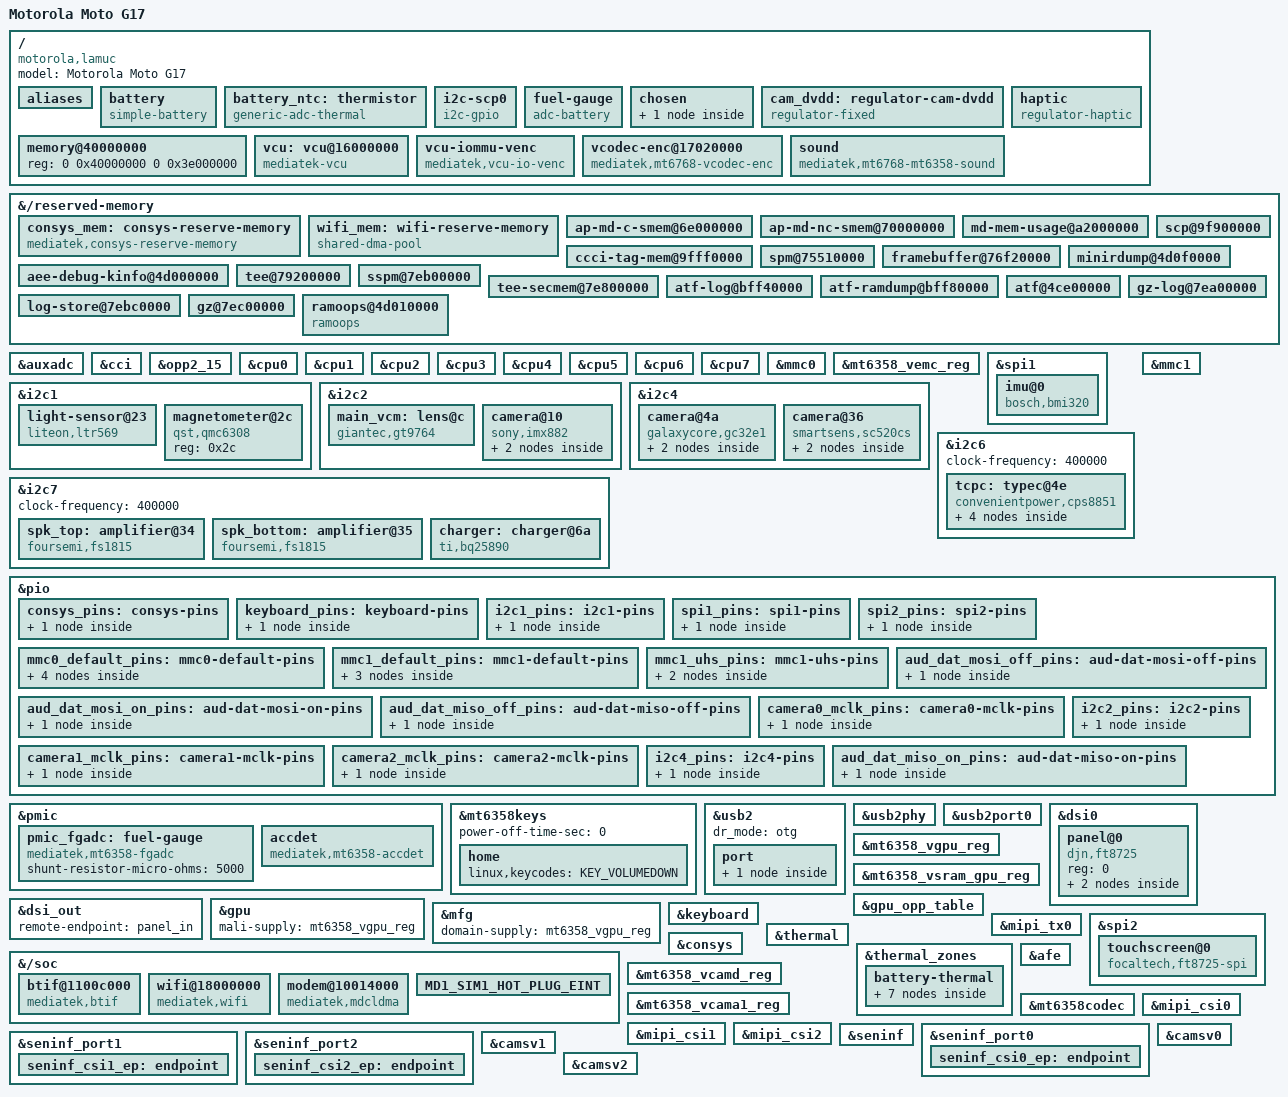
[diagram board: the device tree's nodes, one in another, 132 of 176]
// SPDX-License-Identifier: GPL-2.0-only
/*
 * Motorola Moto G17 (lamuc), booted from U-Boot chainloaded by stock lk.
 * MT6358 regulators, display on lk's panel init.
 */

/dts-v1/;

#include "mt6768.dtsi"
#include "mt6358.dtsi"
#include <dt-bindings/gpio/gpio.h>
#include <dt-bindings/iio/adc/mediatek,mt6358-auxadc.h>
#include <dt-bindings/usb/pd.h>

/ {
	model = "Motorola Moto G17";
	compatible = "motorola,lamuc", "mediatek,mt6768";

	aliases {
		mmc0 = &mmc0;
		mmc1 = &mmc1;
	};

	/* vendor gauge profile battery1_profile_t1 (25 C); battery ID unread */
	battery: battery {
		compatible = "simple-battery";
		device-chemistry = "lithium-ion-polymer";
		charge-full-design-microamp-hours = <5200000>;
		voltage-min-design-microvolt = <3400000>;
		voltage-max-design-microvolt = <4448000>;
		/* measured, 49 mV sag at 623 mA (profile: 88-93 mOhm at 25 C) */
		factory-internal-resistance-micro-ohms = <80000>;
		ocv-capacity-celsius = <25>;
		ocv-capacity-table-0 = <4461000 100>, <4400974 95>, <4349768 90>,
			<4293264 85>, <4232175 80>, <4170600 75>, <4112594 70>,
			<4058013 65>, <4008020 60>, <3946004 55>, <3896000 50>,
			<3864312 45>, <3838800 40>, <3817727 35>, <3799709 30>,
			<3775875 25>, <3752462 20>, <3722573 15>, <3696189 10>,
			<3667100 5>, <3205000 0>;
	};

	/*
	 * 10k NTC (vendor table = NCP15XH103), 24k pull-up to 2.8 V. As
	 * generic-adc-thermal so the fuel gauge can read it over IIO.
	 */
	battery_ntc: thermistor {
		compatible = "generic-adc-thermal";
		io-channels = <&pmic_adc MT6358_AUXADC_BAT_TEMP>;
		io-channel-names = "sensor-channel";
		#io-channel-cells = <0>;
		#thermal-sensor-cells = <0>;
		/* mV = 2800 * R / (R + 24k) at 5 C steps */
		temperature-lookup-table =
			<(-40000) 2494>, <(-35000) 2410>, <(-30000) 2311>,
			<(-25000) 2198>, <(-20000) 2071>, <(-15000) 1935>,
			<(-10000) 1790>, <(-5000) 1639>, <0 1488>,
			<5000 1340>, <10000 1197>, <15000 1062>,
			<20000 938>, <25000 824>, <30000 720>, <35000 629>,
			<40000 548>, <45000 476>, <50000 414>, <55000 359>,
			<60000 312>, <65000 272>, <70000 238>, <75000 208>,
			<80000 182>, <85000 160>, <90000 141>, <95000 124>,
			<100000 109>, <105000 97>, <110000 86>, <115000 76>,
			<120000 68>, <125000 61>;
	};

	/* the SCP's other sensor bus (SCP_SDA0/SCL0); no AP I2C function there */
	i2c-scp0 {
		compatible = "i2c-gpio";
		sda-gpios = <&pio 15 (GPIO_ACTIVE_HIGH | GPIO_OPEN_DRAIN)>;
		scl-gpios = <&pio 16 (GPIO_ACTIVE_HIGH | GPIO_OPEN_DRAIN)>;
		i2c-gpio,delay-us = <2>;
		#address-cells = <1>;
		#size-cells = <0>;
	};

	fuel-gauge {
		compatible = "adc-battery";
		io-channels = <&pmic_adc MT6358_AUXADC_BATADC>, <&pmic_fgadc>,
			      <&battery_ntc>;
		io-channel-names = "voltage", "current", "temperature";
		monitored-battery = <&battery>;
		power-supplies = <&charger>;
	};

	chosen {
		/* lk's second framebuffer page, what the panel scans out */
		framebuffer@77916000 {
			compatible = "simple-framebuffer";
			reg = <0 0x77916000 0 (1080 * 2400 * 4)>;
			width = <1080>;
			height = <2400>;
			stride = <(1080 * 4)>;
			format = "a8r8g8b8";
		};
	};

	/* DVDD of the front (GC32E1) and auxiliary (SC520CS) cameras */
	cam_dvdd: regulator-cam-dvdd {
		compatible = "regulator-fixed";
		regulator-name = "cam_dvdd";
		regulator-min-microvolt = <1200000>;
		regulator-max-microvolt = <1200000>;
		gpio = <&pio 178 GPIO_ACTIVE_HIGH>;
		enable-active-high;
	};

	/* stock vib_vol 9 is VIBR VOSEL 9, 2.8 V */
	haptic {
		compatible = "regulator-haptic";
		haptic-supply = <&mt6358_vibr_reg>;
		min-microvolt = <2800000>;
		max-microvolt = <2800000>;
	};

	/* replaced by U-Boot with lk's figure */
	memory@40000000 {
		device_type = "memory";
		reg = <0 0x40000000 0 0x3e000000>;
	};
};

/*
 * lk's mblock reservations (recon/lk-memory-map.txt). Listing them here,
 * with no-map, makes U-Boot skip its own copies, which carry no no-map.
 */
&{/reserved-memory} {
	/* vendor CONNSYS stack (tools/build-wifi.sh); 16 MiB aligned for the EMI remap */
	consys_mem: consys-reserve-memory {
		compatible = "mediatek,consys-reserve-memory";
		no-map;
		size = <0 0x400000>;
		alignment = <0 0x1000000>;
		alloc-ranges = <0 0x40000000 0 0x80000000>;
	};

	wifi_mem: wifi-reserve-memory {
		compatible = "shared-dma-pool";
		no-map;
		size = <0 0x410000>;
		alignment = <0 0x1000000>;
		alloc-ranges = <0 0x40000000 0 0x80000000>;
	};

	ap-md-c-smem@6e000000 {
		reg = <0x0 0x6e000000 0x0 0x01620000>;
		no-map;
	};
	ap-md-nc-smem@70000000 {
		reg = <0x0 0x70000000 0x0 0x008e0000>;
		no-map;
	};
	md-mem-usage@a2000000 {
		reg = <0x0 0xa2000000 0x0 0x10000000>;
		no-map;
	};
	ccci-tag-mem@9fff0000 {
		reg = <0x0 0x9fff0000 0x0 0x00010000>;
		no-map;
	};
	scp@9f900000 {
		reg = <0x0 0x9f900000 0x0 0x00600000>;
		no-map;
	};
	spm@75510000 {
		reg = <0x0 0x75510000 0x0 0x00010000>;
		no-map;
	};
	framebuffer@76f20000 {
		reg = <0x0 0x76f20000 0x0 0x022e0000>;
		no-map;
	};
	minirdump@4d0f0000 {
		reg = <0x0 0x4d0f0000 0x0 0x00010000>;
		no-map;
	};
	aee-debug-kinfo@4d000000 {
		reg = <0x0 0x4d000000 0x0 0x00010000>;
		no-map;
	};
	tee@79200000 {
		reg = <0x0 0x79200000 0x0 0x05600000>;
		no-map;
	};
	sspm@7eb00000 {
		reg = <0x0 0x7eb00000 0x0 0x000c0000>;
		no-map;
	};
	tee-secmem@7e800000 {
		reg = <0x0 0x7e800000 0x0 0x00200000>;
		no-map;
	};
	atf-log@bff40000 {
		reg = <0x0 0xbff40000 0x0 0x00040000>;
		no-map;
	};
	atf-ramdump@bff80000 {
		reg = <0x0 0xbff80000 0x0 0x00080000>;
		no-map;
	};
	atf@4ce00000 {
		reg = <0x0 0x4ce00000 0x0 0x00060000>;
		no-map;
	};
	log-store@7ebc0000 {
		reg = <0x0 0x7ebc0000 0x0 0x00040000>;
		no-map;
	};
	gz-log@7ea00000 {
		reg = <0x0 0x7ea00000 0x0 0x00041000>;
		no-map;
	};
	gz@7ec00000 {
		reg = <0x0 0x7ec00000 0x0 0x01400000>;
		no-map;
	};

	/* console zone at +0x20000 is where U-Boot's memlog writes too */
	ramoops@4d010000 {
		compatible = "ramoops";
		reg = <0 0x4d010000 0 0xe0000>;
		record-size = <0x10000>;
		console-size = <0x40000>;
		pmsg-size = <0x80000>;
	};
};

&auxadc {
	status = "okay";
};

&cci {
	proc-supply = <&mt6358_vproc12_reg>;
	sram-supply = <&mt6358_vsram_proc12_reg>;
};

/* vendor's top CCI OPP; the dtsi's 1277 MHz @ 1006 mV is not in the k68 tables */
&opp2_15 {
	opp-hz = /bits/ 64 <1187000000>;
	opp-microvolt = <943750>;
};

&cpu0 {
	proc-supply = <&mt6358_vproc12_reg>;
	sram-supply = <&mt6358_vsram_proc12_reg>;
};

&cpu1 {
	proc-supply = <&mt6358_vproc12_reg>;
	sram-supply = <&mt6358_vsram_proc12_reg>;
};

&cpu2 {
	proc-supply = <&mt6358_vproc12_reg>;
	sram-supply = <&mt6358_vsram_proc12_reg>;
};

&cpu3 {
	proc-supply = <&mt6358_vproc12_reg>;
	sram-supply = <&mt6358_vsram_proc12_reg>;
};

&cpu4 {
	proc-supply = <&mt6358_vproc12_reg>;
	sram-supply = <&mt6358_vsram_proc12_reg>;
};

&cpu5 {
	proc-supply = <&mt6358_vproc12_reg>;
	sram-supply = <&mt6358_vsram_proc12_reg>;
};

&cpu6 {
	proc-supply = <&mt6358_vproc11_reg>;
	sram-supply = <&mt6358_vsram_proc11_reg>;
};

&cpu7 {
	proc-supply = <&mt6358_vproc11_reg>;
	sram-supply = <&mt6358_vsram_proc11_reg>;
};

/* eMMC, conservatively: high speed only, no hw reset, no CQE */
&mmc0 {
	pinctrl-names = "default", "state_uhs";
	pinctrl-0 = <&mmc0_default_pins>;
	pinctrl-1 = <&mmc0_default_pins>;
	bus-width = <8>;
	max-frequency = <200000000>;
	cap-mmc-highspeed;
	mmc-hs200-1_8v;
	mmc-hs400-1_8v;
	hs400-ds-delay = <0x12814>;
	non-removable;
	no-sd;
	no-sdio;
	vmmc-supply = <&mt6358_vemc_reg>;
	vqmmc-supply = <&mt6358_vio18_reg>;
	status = "okay";
};

&mt6358_vemc_reg {
	regulator-min-microvolt = <3000000>;
	regulator-max-microvolt = <3000000>;
};

/* microSD, conservatively: high speed only */
&spi1 {
	pinctrl-names = "default";
	pinctrl-0 = <&spi1_pins>;
	/* SPI1_A_* */
	mediatek,pad-select = <0>;
	status = "okay";

	imu@0 {
		compatible = "bosch,bmi320", "bosch,bmi323";
		reg = <0>;
		spi-max-frequency = <10000000>;
		mount-matrix = "0", "-1", "0",
			       "1", "0", "0",
			       "0", "0", "1";
	};
};

/* sensors, behind the SCP on stock */
&i2c1 {
	clock-frequency = <400000>;
	pinctrl-names = "default";
	pinctrl-0 = <&i2c1_pins>;
	status = "okay";

	light-sensor@23 {
		compatible = "liteon,ltr569";
		reg = <0x23>;
		/* ~280 counts open, thousands when covered */
		proximity-near-level = <1500>;
	};

	magnetometer@2c {
		compatible = "qst,qmc6308";
		reg = <0x2c>;
	};
};

/* pins muxed by the bootloader, as in the vendor DT */
/* main rear camera */
&i2c2 {
	clock-frequency = <400000>;
	pinctrl-names = "default";
	pinctrl-0 = <&i2c2_pins>;
	status = "okay";

	main_vcm: lens@c {
		compatible = "giantec,gt9764";
		reg = <0x0c>;
		vdd-supply = <&mt6358_vldo28_reg>;
	};

	camera@10 {
		compatible = "sony,imx882";
		reg = <0x10>;
		pinctrl-names = "default";
		pinctrl-0 = <&camera0_mclk_pins>;
		clocks = <&topckgen CLK_TOP_CAMTG_SEL>;
		assigned-clocks = <&topckgen CLK_TOP_CAMTG_SEL>;
		assigned-clock-parents = <&topckgen CLK_TOP_USB20_192M_D8>;
		reset-gpios = <&pio 101 GPIO_ACTIVE_LOW>;
		dovdd-supply = <&mt6358_vcamio_reg>;
		dvdd-supply = <&mt6358_vcamd_reg>;
		avdd-supply = <&mt6358_vcama1_reg>;
		lens-focus = <&main_vcm>;
		orientation = <1>;
		rotation = <90>;

		port {
			imx882_ep: endpoint {
				remote-endpoint = <&seninf_csi0_ep>;
				data-lanes = <1 2 3 4>;
				link-frequencies = /bits/ 64 <500000000 878000000>;
			};
		};
	};
};

/* front and auxiliary rear cameras */
&i2c4 {
	clock-frequency = <400000>;
	pinctrl-names = "default";
	pinctrl-0 = <&i2c4_pins>;
	status = "okay";

	camera@4a {
		compatible = "galaxycore,gc32e1";
		reg = <0x4a>;
		pinctrl-names = "default";
		pinctrl-0 = <&camera1_mclk_pins>;
		clocks = <&topckgen CLK_TOP_CAMTG1_SEL>;
		assigned-clocks = <&topckgen CLK_TOP_CAMTG1_SEL>;
		assigned-clock-parents = <&topckgen CLK_TOP_USB20_192M_D8>;
		reset-gpios = <&pio 109 GPIO_ACTIVE_LOW>;
		dovdd-supply = <&mt6358_vcamio_reg>;
		dvdd-supply = <&cam_dvdd>;
		avdd-supply = <&mt6358_vcama2_reg>;
		orientation = <0>;
		rotation = <90>;

		port {
			gc32e1_ep: endpoint {
				remote-endpoint = <&seninf_csi2_ep>;
				data-lanes = <1 2 3 4>;
				link-frequencies = /bits/ 64 <403200000>;
			};
		};
	};

	camera@36 {
		compatible = "smartsens,sc520cs";
		reg = <0x36>;
		pinctrl-names = "default";
		pinctrl-0 = <&camera2_mclk_pins>;
		clocks = <&topckgen CLK_TOP_CAMTG2_SEL>;
		assigned-clocks = <&topckgen CLK_TOP_CAMTG2_SEL>;
		assigned-clock-parents = <&topckgen CLK_TOP_USB20_192M_D8>;
		reset-gpios = <&pio 102 GPIO_ACTIVE_LOW>;
		dovdd-supply = <&mt6358_vcamio_reg>;
		dvdd-supply = <&cam_dvdd>;
		avdd-supply = <&mt6358_vcama2_reg>;
		orientation = <1>;
		rotation = <270>;

		port {
			sc520cs_ep: endpoint {
				remote-endpoint = <&seninf_csi1_ep>;
				data-lanes = <1 2>;
				link-frequencies = /bits/ 64 <450000000>;
			};
		};
	};
};

&i2c6 {
	clock-frequency = <400000>;
	status = "okay";

	/*
	 * CPS8851, an RT1711H-style TCPC (VID 0x315c). The vendor DT puts it
	 * at 0x4a and an sc2150 at 0x4e; on this unit only 0x4e answers, with
	 * the CPS8851 IDs.
	 */
	tcpc: typec@4e {
		compatible = "convenientpower,cps8851";
		reg = <0x4e>;
		interrupts-extended = <&pio 4 IRQ_TYPE_LEVEL_LOW>;

		connector {
			compatible = "usb-c-connector";
			label = "USB-C";
			/* sink only until VBUS out (charger boost) is wired up */
			power-role = "sink";
			/* PD hard reset resets the CPS8851's registers; TCPM then loses the port */
			pd-disable;
			typec-power-opmode = "default";
			self-powered;
			data-role = "device";
			sink-pdos = <PDO_FIXED(5000, 2000, PDO_FIXED_USB_COMM)>;
			op-sink-microwatt = <10000000>;

			ports {
				#address-cells = <1>;
				#size-cells = <0>;

				port@0 {
					reg = <0>;

					tcpc_hs: endpoint {
						remote-endpoint = <&usb_role_sw>;
					};
				};
			};
		};
	};
};

&i2c7 {
	clock-frequency = <400000>;
	status = "okay";

	/* analog in from the MT6358 receiver output; earpiece, doubles as top speaker */
	spk_top: amplifier@34 {
		compatible = "foursemi,fs1815";
		reg = <0x34>;
		sound-name-prefix = "Top";
	};

	/* analog in from the MT6358 LINEOUT L */
	spk_bottom: amplifier@35 {
		compatible = "foursemi,fs1815";
		reg = <0x35>;
		sound-name-prefix = "Bottom";
	};

	/* Suncore CX25890H, a register-compatible BQ25890 clone (same PN) */
	charger: charger@6a {
		compatible = "ti,bq25890";
		reg = <0x6a>;
		interrupts-extended = <&pio 3 IRQ_TYPE_EDGE_FALLING>;
		/* Type-C current advertisement for IINLIM */
		power-supplies = <&tcpc>;
		/* lk leaves it charging; /CE is GPIO150, held low by lk */
		linux,skip-reset;
		/* TS is not the battery NTC: JEITA is battery-thermal's job */
		ti,charge-current = <2048000>;
		ti,battery-regulation-voltage = <4448000>;
		ti,termination-current = <256000>;
		ti,precharge-current = <128000>;
		ti,minimum-sys-voltage = <3500000>;
		ti,boost-voltage = <5126000>;
		ti,boost-max-current = <1650000>;
		#cooling-cells = <2>;
	};
};

&mmc1 {
	pinctrl-names = "default", "state_uhs";
	pinctrl-0 = <&mmc1_default_pins>;
	pinctrl-1 = <&mmc1_uhs_pins>;
	bus-width = <4>;
	max-frequency = <200000000>;
	cap-sd-highspeed;
	sd-uhs-sdr12;
	sd-uhs-sdr25;
	sd-uhs-sdr50;
	sd-uhs-sdr104;
	sd-uhs-ddr50;
	no-mmc;
	no-sdio;
	cd-gpios = <&pio 18 GPIO_ACTIVE_HIGH>;
	vmmc-supply = <&mt6358_vmch_reg>;
	vqmmc-supply = <&mt6358_vmc_reg>;
	status = "okay";
};

&pio {
	consys_pins: consys-pins {
		pins-adie {
			pinmux = <PINMUX_GPIO113__FUNC_CONN_TOP_CLK>,
				 <PINMUX_GPIO114__FUNC_CONN_TOP_DATA>,
				 <PINMUX_GPIO115__FUNC_CONN_BT_CLK>,
				 <PINMUX_GPIO116__FUNC_CONN_BT_DATA>,
				 <PINMUX_GPIO117__FUNC_CONN_WF_CTRL0>,
				 <PINMUX_GPIO118__FUNC_CONN_WF_CTRL1>,
				 <PINMUX_GPIO119__FUNC_CONN_WF_CTRL2>,
				 <PINMUX_GPIO120__FUNC_CONN_WB_PTA>,
				 <PINMUX_GPIO121__FUNC_CONN_HRST_B>;
		};
	};

	keyboard_pins: keyboard-pins {
		pins-col {
			pinmux = <PINMUX_GPIO93__FUNC_KPCOL0>;
			bias-pull-up = <MTK_PUPD_SET_R1R0_10>;
			input-enable;
			input-schmitt-enable;
		};
	};

	/* stock muxes these to the SCP (SCP_SCL1/SDA1) for its sensor hub */
	i2c1_pins: i2c1-pins {
		pins-bus {
			pinmux = <PINMUX_GPIO81__FUNC_SDA1>,
				 <PINMUX_GPIO84__FUNC_SCL1>;
		};
	};

	/* SCP_SPI1 on stock, where the sensor hub firmware drives the IMU */
	spi1_pins: spi1-pins {
		pins-spi {
			pinmux = <PINMUX_GPIO85__FUNC_SPI1_A_MI>,
				 <PINMUX_GPIO86__FUNC_SPI1_A_CSB>,
				 <PINMUX_GPIO87__FUNC_SPI1_A_MO>,
				 <PINMUX_GPIO88__FUNC_SPI1_A_CLK>;
		};
	};

	spi2_pins: spi2-pins {
		pins-spi {
			pinmux = <PINMUX_GPIO25__FUNC_SPI2_CSB>,
				 <PINMUX_GPIO26__FUNC_SPI2_MO>,
				 <PINMUX_GPIO27__FUNC_SPI2_CLK>,
				 <PINMUX_GPIO28__FUNC_SPI2_MI>;
		};
	};

	/* SoC-fixed MSDC0 pins, as on penangf */
	mmc0_default_pins: mmc0-default-pins {
		pins-clk {
			pinmux = <PINMUX_GPIO124__FUNC_MSDC0_CLK>;
			drive-strength = <MTK_DRIVE_4mA>;
			bias-pull-down = <MTK_PUPD_SET_R1R0_10>;
		};

		pins-cmd-dat {
			pinmux = <PINMUX_GPIO123__FUNC_MSDC0_DAT0>,
				 <PINMUX_GPIO128__FUNC_MSDC0_DAT1>,
				 <PINMUX_GPIO125__FUNC_MSDC0_DAT2>,
				 <PINMUX_GPIO132__FUNC_MSDC0_DAT3>,
				 <PINMUX_GPIO126__FUNC_MSDC0_DAT4>,
				 <PINMUX_GPIO129__FUNC_MSDC0_DAT5>,
				 <PINMUX_GPIO127__FUNC_MSDC0_DAT6>,
				 <PINMUX_GPIO130__FUNC_MSDC0_DAT7>,
				 <PINMUX_GPIO122__FUNC_MSDC0_CMD>;
			input-enable;
			drive-strength = <MTK_DRIVE_4mA>;
			bias-pull-up = <MTK_PUPD_SET_R1R0_01>;
		};

		pins-ds {
			pinmux = <PINMUX_GPIO131__FUNC_MSDC0_DSL>;
			drive-strength = <MTK_DRIVE_4mA>;
		};

		pins-rst {
			pinmux = <PINMUX_GPIO133__FUNC_MSDC0_RSTB>;
			drive-strength = <MTK_DRIVE_6mA>;
			bias-pull-up = <MTK_PUPD_SET_R1R0_01>;
		};
	};

	/* raw drive values (mt6768 uses drive_set_raw): 3 = 8 mA, as stock */
	mmc1_default_pins: mmc1-default-pins {
		pins-cmd-dat {
			pinmux = <PINMUX_GPIO164__FUNC_MSDC1_DAT0>,
				 <PINMUX_GPIO163__FUNC_MSDC1_DAT1>,
				 <PINMUX_GPIO162__FUNC_MSDC1_DAT2>,
				 <PINMUX_GPIO161__FUNC_MSDC1_DAT3>,
				 <PINMUX_GPIO170__FUNC_MSDC1_CMD>;
			input-enable;
			input-schmitt-enable;
			drive-strength = <3>;
			bias-pull-up = <MTK_PUPD_SET_R1R0_01>;
		};

		pins-clk {
			pinmux = <PINMUX_GPIO171__FUNC_MSDC1_CLK>;
			input-schmitt-enable;
			drive-strength = <3>;
			bias-pull-down = <MTK_PUPD_SET_R1R0_10>;
		};

		pins-insert {
			pinmux = <PINMUX_GPIO18__FUNC_GPIO18>;
			bias-pull-up;
		};
	};

	/* stock's UHS state: as default, CLK without the pull */
	mmc1_uhs_pins: mmc1-uhs-pins {
		pins-cmd-dat {
			pinmux = <PINMUX_GPIO164__FUNC_MSDC1_DAT0>,
				 <PINMUX_GPIO163__FUNC_MSDC1_DAT1>,
				 <PINMUX_GPIO162__FUNC_MSDC1_DAT2>,
				 <PINMUX_GPIO161__FUNC_MSDC1_DAT3>,
				 <PINMUX_GPIO170__FUNC_MSDC1_CMD>;
			input-enable;
			input-schmitt-enable;
			drive-strength = <3>;
			bias-pull-up = <MTK_PUPD_SET_R1R0_01>;
		};

		pins-clk {
			pinmux = <PINMUX_GPIO171__FUNC_MSDC1_CLK>;
			input-schmitt-enable;
			drive-strength = <3>;
		};
	};

};

&pmic {
	interrupts-extended = <&pio 144 IRQ_TYPE_LEVEL_HIGH>;

	pmic_fgadc: fuel-gauge {
		compatible = "mediatek,mt6358-fgadc";
		#io-channel-cells = <0>;
		/* stock R_FG_VALUE */
		shunt-resistor-micro-ohms = <5000>;
	};

	/* stock settings: MICBIAS1 2.6 V, ACC mic, EINT0 active low */
	accdet: accdet {
		compatible = "mediatek,mt6358-accdet";
		io-channels = <&pmic_adc MT6358_AUXADC_ACCDET>;
		io-channel-names = "accdet";
		mediatek,mic-vol = <6>;
		mediatek,eint-level-pol = <IRQ_TYPE_LEVEL_LOW>;
		mediatek,pwm-deb-setting = <0x500 0x500 0x1 0x1f0 0x800 0x800
					    0x20 0x44 0x0 0x0 0xe 0x0 0x0 0x0 0x0>;
		mediatek,three-key-thr = <0 80 220 400>;
	};
};

/* the PMIC "home" key is Volume Down on this phone */
&mt6358keys {
	/* raw RST_TD code, not seconds: 0 as on stock */
	power-off-time-sec = <0>;

	home {
		linux,keycodes = <KEY_VOLUMEDOWN>;
	};
};

&usb2 {
	dr_mode = "otg";
	status = "okay";

	port {
		usb_role_sw: endpoint {
			remote-endpoint = <&tcpc_hs>;
		};
	};
};

&usb2phy {
	status = "okay";
};

/* stock u2port0 tuning; INTR_CAL stays the efuse autoload */
&usb2port0 {
	mediatek,discth = <7>;
	mediatek,eye-vrt = <7>;
	mediatek,eye-term = <3>;
	mediatek,pre-emphasis = <3>;
};

&dsi0 {
	#address-cells = <1>;
	#size-cells = <0>;
	status = "okay";

	/* lk powers it up and sends the init sequence; see recon/dtbo/dtbo0.dts */
	panel@0 {
		compatible = "djn,ft8725";
		reg = <0>;

		port {
			panel_in: endpoint {
				remote-endpoint = <&dsi_out>;
			};
		};
	};
};

&dsi_out {
	remote-endpoint = <&panel_in>;
};

&gpu {
	mali-supply = <&mt6358_vgpu_reg>;
	status = "okay";
};

&mfg {
	domain-supply = <&mt6358_vgpu_reg>;
};

&mt6358_vgpu_reg {
	regulator-max-microvolt = <800000>;
	regulator-coupled-with = <&mt6358_vsram_gpu_reg>;
	regulator-coupled-max-spread = <100000>;
};

/* vendor: vsram = vgpu + 100 mV */
&mt6358_vsram_gpu_reg {
	/* only coupled to vgpu, nothing else enables it */
	regulator-always-on;
	regulator-min-microvolt = <850000>;
	regulator-max-microvolt = <1050000>;
	regulator-coupled-with = <&mt6358_vgpu_reg>;
	regulator-coupled-max-spread = <100000>;
};

/* the vendor caps MT6768/MT6769 parts at 823 MHz (OPP 7); G85-class go to 1 GHz */
&gpu_opp_table {
	/delete-node/ opp-850000000;
	/delete-node/ opp-875000000;
	/delete-node/ opp-900000000;
	/delete-node/ opp-925000000;
	/delete-node/ opp-950000000;
	/delete-node/ opp-975000000;
	/delete-node/ opp-1000000000;
};

&keyboard {
	pinctrl-names = "default";
	pinctrl-0 = <&keyboard_pins>;
	linux,keymap = <MATRIX_KEY(0x00, 0x00, KEY_VOLUMEUP)>;
	keypad,num-rows = <1>;
	keypad,num-columns = <1>;
	debounce-delay-ms = <32>;
	status = "okay";
};

&mipi_tx0 {
	status = "okay";
};

&spi2 {
	pinctrl-names = "default";
	pinctrl-0 = <&spi2_pins>;
	mediatek,pad-select = <0>;
	status = "okay";

	/* touch side of the FT8725 TDDI, firmware already running */
	touchscreen@0 {
		compatible = "focaltech,ft8725-spi";
		reg = <0>;
		spi-max-frequency = <9600000>;
		/* the vendor driver says mode 0, but only mode 3 gets answers */
		spi-cpol;
		spi-cpha;
		interrupts-extended = <&pio 0 IRQ_TYPE_EDGE_FALLING>;
		reset-gpios = <&pio 36 GPIO_ACTIVE_LOW>;
		/* reports display pixels, same orientation (checked with evtest) */
		touchscreen-size-x = <1080>;
		touchscreen-size-y = <2400>;
	};
};

&thermal {
	status = "okay";
};

&thermal_zones {
	/* vendor JEITA: 4.2 V and less current above 45 C, none above 60 C */
	battery-thermal {
		polling-delay-passive = <5000>;
		polling-delay = <10000>;
		thermal-sensors = <&battery_ntc>;

		trips {
			battery_warm: trip-warm {
				temperature = <45000>;
				hysteresis = <3000>;
				type = "passive";
			};

			battery_hot: trip-hot {
				temperature = <60000>;
				hysteresis = <3000>;
				type = "passive";
			};

			trip-crit {
				temperature = <68000>;
				hysteresis = <0>;
				type = "critical";
			};
		};

		cooling-maps {
			map-warm {
				trip = <&battery_warm>;
				cooling-device = <&charger 1 2>;
			};

			map-hot {
				trip = <&battery_hot>;
				cooling-device = <&charger 3 3>;
			};
		};
	};
};

/*
 * Vendor wmt_drv/btif/gen4m bindings, as in the stock DT: they index reg and
 * interrupts by position. mtk-consys (same compatible) is off for this.
 * Stock's GIC flags are inverted here: its HIGH is LOW behind sysirq.
 */
&consys {
	reg = <0 0x18002000 0 0x1000>, <0 0x10007000 0 0x100>,
	      <0 0x10001000 0 0x1000>, <0 0x10006000 0 0x1000>,
	      <0 0x18007000 0 0x1000>, <0 0x180b1000 0 0x1000>,
	      <0 0x180a3000 0 0x1000>, <0 0x180a5000 0 0x800>,
	      <0 0x180c1000 0 0x1000>, <0 0x18004000 0 0x1000>;
	interrupts = <GIC_SPI 284 IRQ_TYPE_LEVEL_LOW>,
		     <GIC_SPI 78 IRQ_TYPE_LEVEL_LOW>,
		     <GIC_SPI 287 IRQ_TYPE_EDGE_FALLING>;
	memory-region = <&consys_mem>;
	pinctrl-names = "default";
	pinctrl-0 = <&consys_pins>;
	vcn18-supply = <&mt6358_vcn18_reg>;
	vcn28-supply = <&mt6358_vcn28_reg>;
	vcn33_bt-supply = <&mt6358_vcn33_reg>;
	vcn33_wifi-supply = <&mt6358_vcn33_reg>;
	status = "okay";
};

&{/soc} {
	btif@1100c000 {
		compatible = "mediatek,btif";
		reg = <0 0x1100c000 0 0x1000>, <0 0x11000b80 0 0x80>,
		      <0 0x11000c00 0 0x80>;
		interrupts = <GIC_SPI 133 IRQ_TYPE_LEVEL_LOW>,
			     <GIC_SPI 115 IRQ_TYPE_LEVEL_LOW>,
			     <GIC_SPI 141 IRQ_TYPE_LEVEL_LOW>;
		clocks = <&infracfg_ao CLK_INFRA_BTIF>,
			 <&infracfg_ao CLK_INFRA_AP_DMA>;
		clock-names = "btifc", "apdmac";
	};

	wifi@18000000 {
		compatible = "mediatek,wifi";
		reg = <0 0x18000000 0 0x100000>;
		interrupts = <GIC_SPI 285 IRQ_TYPE_LEVEL_LOW>;
		memory-region = <&wifi_mem>;
	};

	/* vendor eccci (modem/ in the g17 repo); MD1 power is done there */
	modem@10014000 {
		compatible = "mediatek,mdcldma";
		reg = <0 0x10014000 0 0x1000>, <0 0x1021b000 0 0x1000>,
		      <0 0x10209000 0 0x1000>, <0 0x1020a000 0 0x1000>;
		interrupts = <GIC_SPI 180 IRQ_TYPE_LEVEL_HIGH>,
			     <GIC_SPI 164 IRQ_TYPE_LEVEL_LOW>,
			     <GIC_SPI 165 IRQ_TYPE_LEVEL_LOW>,
			     <GIC_SPI 75 IRQ_TYPE_EDGE_FALLING>;
		clocks = <&infracfg_ao CLK_INFRA_CLDMA_BCLK>,
			 <&infracfg_ao CLK_INFRA_CCIF_AP>,
			 <&infracfg_ao CLK_INFRA_CCIF_MD>,
			 <&infracfg_ao CLK_INFRA_CCIF1_AP>,
			 <&infracfg_ao CLK_INFRA_CCIF1_MD>,
			 <&infracfg_ao CLK_INFRA_CCIF2_AP>,
			 <&infracfg_ao CLK_INFRA_CCIF2_MD>;
		clock-names = "infra-cldma-bclk", "infra-ccif-ap",
			      "infra-ccif-md", "infra-ccif1-ap",
			      "infra-ccif1-md", "infra-ccif2-ap",
			      "infra-ccif2-md";
		md-vmodem-supply = <&mt6358_vmodem_reg>;
		md-vmodem-microvolt = <750000>;
		mediatek,md_id = <0>;
		mediatek,cldma_capability = <6>;
		mediatek,mdhif_type = <3>;
	};

	/* SIM1 detect for the modem, stock dtbo values; eccci finds it by name */
	MD1_SIM1_HOT_PLUG_EINT {
		interrupts = <0 8>;
		debounce = <0 10000>;
		dedicated = <0 0>;
		src_pin = <0 1>;
		sockettype = <0 0>;
	};
};

&afe {
	pinctrl-names = "aud_dat_mosi_off", "aud_dat_mosi_on",
			"aud_dat_miso_off", "aud_dat_miso_on";
	pinctrl-0 = <&aud_dat_mosi_off_pins>;
	pinctrl-1 = <&aud_dat_mosi_on_pins>;
	pinctrl-2 = <&aud_dat_miso_off_pins>;
	pinctrl-3 = <&aud_dat_miso_on_pins>;
};

/ {

	/*
	 * H.264 encoder through the vendor VCU stack (nix/venc.nix): vpud
	 * programs VENC from userspace, mtk-vcu forwards its GCE command lists.
	 * The reg list is vpud's register map, in stock's order.
	 */
	vcu: vcu@16000000 {
		compatible = "mediatek-vcu";
		reg = <0 0x16000000 0 0x40000>,
		      <0 0x17020000 0 0x10000>,
		      <0 0x19002000 0 0x1000>;
		iommus = <&iommu M4U_PORT_VENC_RCPU>, <&iommu M4U_PORT_VENC_REC>,
			 <&iommu M4U_PORT_VENC_BSDMA>, <&iommu M4U_PORT_VENC_SV_COMV>,
			 <&iommu M4U_PORT_VENC_RD_COMV>, <&iommu M4U_PORT_VENC_CUR_LUMA>,
			 <&iommu M4U_PORT_VENC_CUR_CHROMA>, <&iommu M4U_PORT_VENC_REF_LUMA>,
			 <&iommu M4U_PORT_VENC_REF_CHROMA>;
		mboxes = <&gce 12 CMDQ_THR_PRIO_1>, <&gce 13 CMDQ_THR_PRIO_1>;
		gce-event-names = "venc_eof", "venc_cmdq_pause_done",
				  "venc_mb_done", "venc_128B_cnt_done";
		mediatek,gce-events = <CMDQ_EVENT_VENC_FRAME_DONE>,
				      <CMDQ_EVENT_VENC_PAUSE_DONE>,
				      <CMDQ_EVENT_VENC_MB_DONE>,
				      <CMDQ_EVENT_VENC_128BYTE_CNT_DONE>;
		gce-norm-token = /bits/ 16 <0x2b8>;
		gce-sec-token = /bits/ 16 <0x2b9>;
		mediatek,vcuid = <0>;
		mediatek,vcuname = "vcu";
		mediatek,vcu-off = <0>;
		mediatek,dec-gce-th-num = <0>;
		mediatek,enc-gce-th-num = <2>;
	};

	vcu-iommu-venc {
		compatible = "mediatek,vcu-io-venc";
		iommus = <&iommu M4U_PORT_VENC_RCPU>, <&iommu M4U_PORT_VENC_REC>,
			 <&iommu M4U_PORT_VENC_BSDMA>, <&iommu M4U_PORT_VENC_SV_COMV>,
			 <&iommu M4U_PORT_VENC_RD_COMV>, <&iommu M4U_PORT_VENC_CUR_LUMA>,
			 <&iommu M4U_PORT_VENC_CUR_CHROMA>, <&iommu M4U_PORT_VENC_REF_LUMA>,
			 <&iommu M4U_PORT_VENC_REF_CHROMA>;
		mediatek,vcuid = <0>;
	};

	vcodec-enc@17020000 {
		compatible = "mediatek,mt6768-vcodec-enc";
		reg = <0 0x17020000 0 0x2000>;
		reg-names = "VENC_SYS";
		interrupts = <GIC_SPI 243 IRQ_TYPE_LEVEL_LOW>;
		iommus = <&iommu M4U_PORT_VENC_RCPU>, <&iommu M4U_PORT_VENC_REC>,
			 <&iommu M4U_PORT_VENC_BSDMA>, <&iommu M4U_PORT_VENC_SV_COMV>,
			 <&iommu M4U_PORT_VENC_RD_COMV>, <&iommu M4U_PORT_VENC_CUR_LUMA>,
			 <&iommu M4U_PORT_VENC_CUR_CHROMA>, <&iommu M4U_PORT_VENC_REF_LUMA>,
			 <&iommu M4U_PORT_VENC_REF_CHROMA>;
		clocks = <&vencsys CLK_VENC_SET1_VENC>;
		clock-names = "MT_CG_VENC";
		mediatek,larbs = <&larb4>;
		mediatek,vcu = <&vcu>;
		mediatek,platform = "platform:mt6768";
		mediatek,ipm = <1>;
		venc-disable-hw-break = <1>;
	};
	sound: sound {
		compatible = "mediatek,mt6768-mt6358-sound";
		mediatek,platform = <&afe>;
		mediatek,accdet = <&accdet>;
		audio-aux-devs = <&spk_top>, <&spk_bottom>;
		audio-routing = "Top IN", "Receiver",
				"Bottom IN", "LINEOUT L";
	};
};

&pio {
	/* mtkaif pads to the MT6358 codec, as in the stock DT */
	aud_dat_mosi_off_pins: aud-dat-mosi-off-pins {
		pins-cmd-dat {
			pinmux = <PINMUX_GPIO136__FUNC_GPIO136>,
				 <PINMUX_GPIO137__FUNC_GPIO137>,
				 <PINMUX_GPIO138__FUNC_GPIO138>,
				 <PINMUX_GPIO139__FUNC_GPIO139>;
			input-enable;
			slew-rate = <0>;
			bias-disable;
		};
	};

	aud_dat_mosi_on_pins: aud-dat-mosi-on-pins {
		pins-cmd-dat {
			pinmux = <PINMUX_GPIO136__FUNC_AUD_CLK_MOSI>,
				 <PINMUX_GPIO137__FUNC_AUD_SYNC_MOSI>,
				 <PINMUX_GPIO138__FUNC_AUD_DAT_MOSI0>,
				 <PINMUX_GPIO139__FUNC_AUD_DAT_MOSI1>;
			input-schmitt-enable;
		};
	};

	aud_dat_miso_off_pins: aud-dat-miso-off-pins {
		pins-cmd-dat {
			pinmux = <PINMUX_GPIO140__FUNC_GPIO140>,
				 <PINMUX_GPIO141__FUNC_GPIO141>,
				 <PINMUX_GPIO142__FUNC_GPIO142>,
				 <PINMUX_GPIO143__FUNC_GPIO143>;
			input-enable;
			slew-rate = <0>;
			bias-disable;
		};
	};

	camera0_mclk_pins: camera0-mclk-pins {
		pins {
			pinmux = <PINMUX_GPIO99__FUNC_CMMCLK0>;
			drive-strength = <4>;
		};
	};

	camera1_mclk_pins: camera1-mclk-pins {
		pins {
			pinmux = <PINMUX_GPIO100__FUNC_CMMCLK1>;
			drive-strength = <4>;
		};
	};

	camera2_mclk_pins: camera2-mclk-pins {
		pins {
			pinmux = <PINMUX_GPIO108__FUNC_CMMCLK2>;
			drive-strength = <6>;
		};
	};

	/* nothing else pulls the camera buses up */
	i2c2_pins: i2c2-pins {
		pins {
			pinmux = <PINMUX_GPIO103__FUNC_SCL2>,
				 <PINMUX_GPIO104__FUNC_SDA2>;
			bias-pull-up;
		};
	};

	i2c4_pins: i2c4-pins {
		pins {
			pinmux = <PINMUX_GPIO105__FUNC_SCL4>,
				 <PINMUX_GPIO106__FUNC_SDA4>;
			bias-pull-up;
		};
	};

	aud_dat_miso_on_pins: aud-dat-miso-on-pins {
		pins-cmd-dat {
			pinmux = <PINMUX_GPIO140__FUNC_AUD_CLK_MISO>,
				 <PINMUX_GPIO141__FUNC_AUD_SYNC_MISO>,
				 <PINMUX_GPIO142__FUNC_AUD_DAT_MISO0>,
				 <PINMUX_GPIO143__FUNC_AUD_DAT_MISO1>;
			input-schmitt-enable;
		};
	};
};

/* the PMIC codec, on the internal mtkaif link */
/* IMX882 core and analog */
&mt6358_vcamd_reg {
	regulator-min-microvolt = <1100000>;
	regulator-max-microvolt = <1100000>;
};

&mt6358_vcama1_reg {
	regulator-min-microvolt = <2800000>;
	regulator-max-microvolt = <2800000>;
};

&mt6358codec {
	status = "okay";
};

&mipi_csi0 {
	status = "okay";
};

&mipi_csi1 {
	status = "okay";
};

&mipi_csi2 {
	status = "okay";
};

&seninf {
	status = "okay";
};

&seninf_port0 {
	seninf_csi0_ep: endpoint {
		remote-endpoint = <&imx882_ep>;
		clock-lanes = <2>;
		data-lanes = <1 3 0 4>;
	};
};

&seninf_port1 {
	seninf_csi1_ep: endpoint {
		remote-endpoint = <&sc520cs_ep>;
		clock-lanes = <2>;
		data-lanes = <1 3>;
	};
};

&seninf_port2 {
	seninf_csi2_ep: endpoint {
		remote-endpoint = <&gc32e1_ep>;
		clock-lanes = <2>;
		data-lanes = <1 3 0 4>;
	};
};

&camsv0 {
	status = "okay";
};

&camsv1 {
	status = "okay";
};

&camsv2 {
	status = "okay";
};
